# TC37XPD register map
Vendor: Infineon; Series: ATVMC; File version: 100
CPU: other r0p0, little endian, MPU, FPU, vendor SysTick, 4 interrupt priority bits
Registers are 32-bit, read-write, reset 0x0 unless marked. A register's access mark holds for its fields unless they carry their own. Offsets are from the block's base; [hi:lo] are bit positions; {n}, {i} and the like mark numbered series.

## PMS (part 2 of 3)
Base 0xF0248000
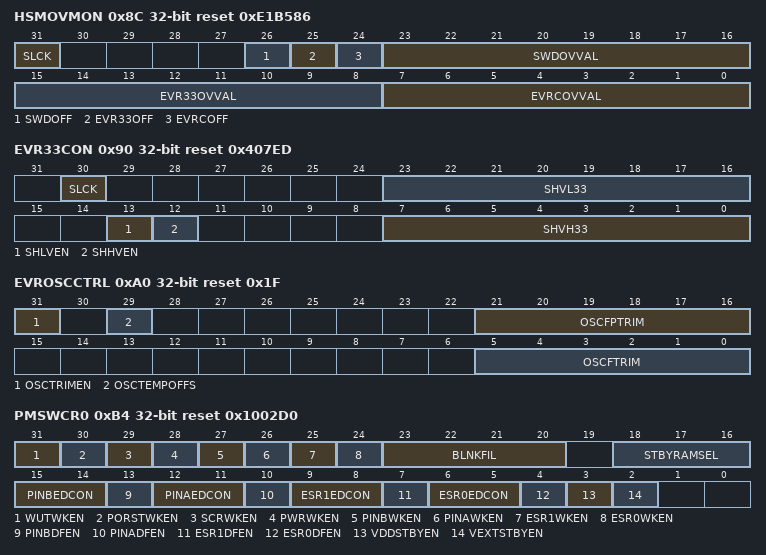
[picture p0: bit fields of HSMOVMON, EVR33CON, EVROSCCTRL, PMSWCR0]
0x8C HSMOVMON reset 0xE1B586 — EVR Primary HSM Over voltage Monitor Register resetvalue={LVD Reset:0x0E1B586,Cold PORST:0x0E1B586,After SSW execution:0x0E1B586}
  [31] SLCK — HSM Security Lock SLCK. If this bit is set all other bits in this register can no longer be written. Write requests to other bits when SLCK is set will trigger an SLCK access error alarm.This bit can not by cleared by software. SLCK bit can only be set by an access from the HSM master TAG 160 160 000011 B . A set operation performed by any other master or software is ignored and the bit is kept as cleared.
  [26] SWDOFF — VEXT Primary Monitor OV Alarm Disable SWDOFF
  [25] EVR33OFF — VDDP3 Primary Monitor OV Alarm Disable EVR33OFF
  [24] EVRCOFF — VDD Primary Monitor OV Alarm Disable EVRCOFF
  [23:16] SWDOVVAL — VEXT Supply Primary Monitor Alarm Over voltage threshold SWDOVVAL. This field defines the over voltage threshold level of the external VEXT supply monitor. SWDOVVAL VDDx 1050 mV LSB LSB 20 mV
  [15:8] EVR33OVVAL — VDDP3 Supply Primary Monitor Alarm Over voltage threshold EVR33OVVAL. This field defines the over voltage monitoring threshold level of the EVR33 regulator output or VDDP3 supply. EVR33OVVAL VDDx 937.5 mV LSB LSB 15 mV
  [7:0] EVRCOVVAL — VDD Supply Primary Monitor Alarm Over voltage threshold EVRCOVVAL. This field defines the over voltage monitoring threshold level of the EVRC regulator output or VDD supply. EVRCOVVAL VDDx 712.5 mV LSB LSB 5 mV
0x90 EVR33CON reset 0x407ED — EVR33 Control Register resetvalue={LVD Reset:0x407ED,Cold PORST:0x407ED,After SSW execution:0x407ED}
  [30] SLCK — HSM Security Lock SLCK. If this bit is set all other bits in this register can no longer be written. Write requests to other bits when SLCK is set will trigger an SLCK access error alarm.This bit can not by cleared by software. SLCK bit can only be set by an access from the HSM master TAG 160 160 000011 B . A set operation performed by any other master or software is ignored and the bit is kept as cleared.
  [23:16] SHVL33 — Short to Ground Voltage Threshold x i SHVL33. This field defines the lower threshold level VDDP3 supply. EVR33 short to ground alarm has the nominal values of SHVL33 1V and t33SHLV 3ms. Do not change the reset value SHVL33 VDDx 937.5 mV LSB LSB 15 mV
  [13] SHLVEN — Short to Low Detection Enable SHLVEN
  [12] SHHVEN — Short to High Detection Enable SHHVEN
  [7:0] SHVH33 — Short to Supply Voltage Threshold x i SHVH33. This field defines the upper threshold level VDDP3 supply. EVR33 short to supply alarm has the nominal values of SHVH33 4.5V and t33SHHV 3ms. Do not change the reset value SHVH33 VDDx 937.5 mV LSB LSB 15 mV
0xA0 EVROSCCTRL reset 0x1F (reset mask 0xDFFFFFFF) — EVR Oscillator Control Register resetvalue={LVD Reset:0x1F,After SSW execution:0x2000001F}
  [31] OSCTRIMEN — Dynamic Oscillator Trim Enable OSCTRIMEN. Based on temperature Oscillator can be trimmed.
  [29] OSCTEMPOFFS — Oscillator Temperature Offset Coefficient OSCTEMPOFFS. This bitfield enables the centering function of the HPOSC temperature coefficient to compensate for technology variations.
  [21:16] OSCFPTRIM — OSC Fine Trim Signed Value OSCFPTRIM. This bit field allows device individual trimming of the oscillator trim value during application. After updating the trim value a waiting time of 1 160 us is required for the change to take effect. OSCTRx is implicitly added to OSCFPTRIM and saturated to range of 32 to 31
  [5:0] OSCFTRIM — Back up Clock Fine Trim Value OSCFTRIM. This thermometer coded bit field contains information about the 100MHz OSC fine trimming. fBACK ftrim OSCFTRIM OSCFPTRIM OSCTRx if OSCTRIMEN 1 LSBFT MHz LSBFT 110kHz Back up Clock accuracy is documented in datasheet. It is recommended to wait 1 160 us after every fine trim step so that the clock source settles at the new frequency. fBACK ftrim value is saturated to range of 64.
0xB4 PMSWCR0 reset 0x1002D0 — Standby and Wake up Control Register 0 resetvalue={LVD Reset:0x1002D0}
  [31] WUTWKEN — WUT Wake up enable from Standby WUTWKEN. This bit configures wake up via WUT from STANDBY mode and current configuration is reflected in PMSWSTAT2.WUTWKEN register bit.
  [30] PORSTWKEN — PORST pin Wake up enable from Standby PORSTWKEN. This bit configures wake up via PORST pin from STANDBY mode and current configuration is reflected in PMSWSTAT2.PORSTWKEN register bit.
  [29] SCRWKEN — Standby Controller Wake up enable from Standby SCRWKEN. This bit configures wake up via SCR from STANDBY mode and current configuration is reflected in PMSWSTAT2.SCRWKEN register bit.
  [28] PWRWKEN — Standby Wake up Enable on VEXT Supply ramp up PWRWKEN. This bit field enables wake up on VEXT supply ramp up after blanking filter time has expired. This is supported only in case Standby domain is supplied separately via VEVRSB supply pin and VEXT rail is switched off during Standby. Current configuration is reflected in PMSWSTAT2.PWRWKEN register bit.
  [27] PINBWKEN — Pin B Wake up enable from Standby PINBWKEN. This bit configures wake up via PINB pin from STANDBY mode and current configuration is reflected in PMSWSTAT2.PINBWKEN register bit.
  [26] PINAWKEN — Pin A Wake up enable from Standby PINAWKEN. This bit configures wake up via PINA pin from STANDBY mode and current configuration is reflected in PMSWSTAT2.PINAWKEN register bit.
  [25] ESR1WKEN — ESR1 Wake up enable from Standby ESR1WKEN. This bit configures wake up via ESR1 pin from STANDBY mode and current configuration is reflected in PMSWSTAT2.ESR1WKEN register bit.
  [24] ESR0WKEN — ESR0 Wake up enable from Standby ESR0WKEN. This bit configures wake up via ESR0 pin from STANDBY mode and current configuration is reflected in PMSWSTAT2.ESR0WKEN register bit.
  [23:20] BLNKFIL — Blanking Filter delay for Wake up BLNKFIL. This bitfield enables a nominal blanking filter delay time immediately after Standby entry only after which a valid wake up event is recognized and reacted upon. The actual delay may vary 160 30 to this nominal value. Current configuration is reflected in PMSWSTAT2.BLNKFIL bitfield. All other bit combinations are reserved. Incase WUT is used as a wake up source the blanking filter should be configured for a period greater than 3x 70kHz clock cycles.
  [18:16] STBYRAMSEL — Standby RAM supply in Standby Mode STBYRAMSEL. This bit field configures the Standby RAM blocks to be kept supplied during Standby Mode from VDDPD supply rail. The current configuration is reflected in PMSWSTAT2.STBYRAM bitfield. All other bit combinations are reserved.
  [15:14] PINBEDCON — PINB Edge Detection Control PINBEDCON. This bit field defines the edge of a Pin B wake up trigger
  [13] PINBDFEN — PINB Digital Filter Enable PINBDFEN. This bit activates digital spike filter. If the digital filter majority filter of 3 consecutive values is enabled during normal RUN mode then pulses less than 40ns are suppressed and pulses longer than 100ns will always result in a trigger. If the back up clock is disabled in Standby mode and filter is running on 70 KHz Standby clock then pulses less than 5 us are suppressed and pulses longer than 50 us will always result in a trigger.
  [12:11] PINAEDCON — PINA Edge Detection Control PINAEDCON. This bit field defines the edge of a Pin A wake up trigger
  [10] PINADFEN — PINA Digital Filter Enable PINADFEN. This bit activates digital spike filter. If the digital filter majority filter of 3 consecutive values is enabled during normal RUN mode then pulses less than 40ns are suppressed and pulses longer than 100ns will always result in a trigger. If the back up clock is disabled in Standby mode and filter is running on 70 KHz Standby clock then pulses less than 5 us are suppressed and pulses longer than 50 us will always result in a trigger.
  [9:8] ESR1EDCON — ESR1 Edge Detection Control ESR1EDCON. This bit field defines the edge of a ESR1 wake up trigger
  [7] ESR1DFEN — ESR1 Digital Filter Enable ESR1DFEN. This bit activates digital spike filter. If the digital filter majority filter of 3 consecutive values is enabled during normal RUN mode then pulses less than 30ns are suppressed and pulses longer than 100ns will always result in a trigger. If the back up clock is disabled in Standby mode and filter is running on 70 KHz Standby clock then pulses less than 5 us are suppressed and pulses longer than 50 us will always result in a trigger.
  [6:5] ESR0EDCON — ESR0 Edge Detection Control ESR0EDCON. This bit field defines the edge of a ESR0 wake up trigger
  [4] ESR0DFEN — ESR0 Digital Filter Enable ESR0DFEN. This bit activates digital spike filter. If the digital filter majority filter of 3 consecutive values is enabled during normal RUN mode then pulses less than 30ns are suppressed and pulses longer than 100ns will always result in a trigger. If the back up clock is disabled in Standby mode and filter is running on 70 160 KHz Standby clock then pulses less than 5 us are suppressed and pulses longer than 50 us will always result in a trigger.
  [3] VDDSTBYEN — Standby Entry on VDD Supply ramp down VDDSTBYEN. This bit field enables Standby Entry on VDD supply ramp down. This is supported only in case Standby domain is supplied separately via VEVRSB supply pin and VDD rail is switched off during Standby. The voltage threshold for entry is configured in EVRUVMON register. Current configuration is reflected in PMSWSTAT2.VDDSTBYEN register bit.
  [2] VEXTSTBYEN — Standby Entry on VEXT Supply ramp down VEXTSTBYEN. This bit field enables Standby Entry on VEXT supply ramp down. This is supported only in case Standby domain is supplied separately via VEVRSB supply pin and VEXT rail is switched off during Standby. The voltage threshold for entry is configured in EVRUVMON register. Current configuration is reflected in PMSWSTAT2.VEXTSTBYEN register bit.
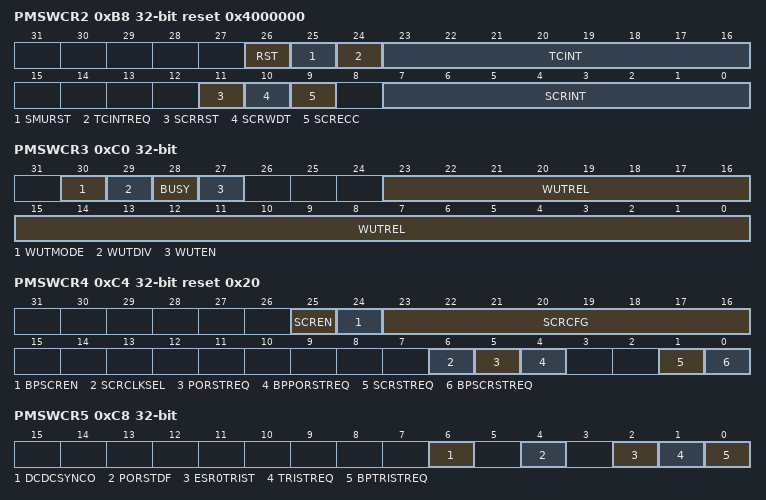
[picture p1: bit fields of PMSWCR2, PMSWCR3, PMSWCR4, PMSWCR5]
0xB8 PMSWCR2 access per field reset 0x4000000 — Standby and Wake up Control Register 2 resetvalue={LVD Reset:0x4000000}
  [26] RST ro — Application or System Reset indication flag RST. SCR is explicitly informed in case of an application or system reset. The flag is cleared after SCR has latched the signal and SCR NMI is issued.
  [25] SMURST ro — SMU Reset indication flag SMURST. SCR is explicitly informed in case reset issued by SMU. The flag is cleared after SCR has latched the signal and SCR NMI is issued.
  [24] TCINTREQ rw — SW Interrupt request from PMS to Standby Controller. TCINTREQ. Setting this bit triggers an interrupt to the 8 bit Standby controller. The TCINTREQ bit is cleared after SCR has latched the TCINT value and SCR NMI is issued.
  [23:16] TCINT rw — Data exchange from PMS main domain to Standby Controller. TCINT. This bit field allows fast data exchange from PMS to SCR. The data may be read by SCR consequent to an interrupt request TCINTREQ from PMS CPUx to SCR to decode the interrupt.
  [11] SCRRST rw — SCR Software reset flag SCRRST. The flag is set by SCR and cleared by explicit write to the register bit. The flag is not cleared by SCR. While the SCR is being reset triggered by SCR software this flag is set and clearing the flag is not possible for that duration.
  [10] SCRWDT rw — SCR Watchdog Timer error reset flag SCRWDT. The flag is set by SCR and cleared by explicit write to the register bit. The flag is not cleared by SCR.While the SCR is being reset triggered by SCR watchdog this flag is set and clearing the flag is not possible for that duration.
  [9] SCRECC rw — SCR RAM ECC error reset flag SCRECC. The flag is set by SCR and cleared by explicit write to the register bit. The flag is not cleared by SCR.While the SCR is being reset triggered by SCR RAM ECC error this flag is set and clearing the flag is not possible for that duration.
  [7:0] SCRINT ro — Data exchange from Standby Controller to PMS main domain. SCRINT. This bit field allows fast data exchange from SCR to PMS CPUx. The data maybe read by CPUx consequent to an interrupt from the SCR to decode the interrupt. Incase SCR is enabled at the end of the SCR Firmware routine a value of 80H is set in SCRINT register to indicate that SCR has finished executing the startup code.
0xC0 PMSWCR3 access per field — Standby and Wake up Control Register 3 resetvalue={LVD Reset:0x0}
  [30] WUTMODE rw — WUT mode selection WUTMODE. This bit configures the Wake up Timer mode. The status bit PMSWSTAT.WUTMODE is respectively updated. A write to this register bitfield may trigger immediate update irrespective of the status of BUSY bit.
  [29] WUTDIV rw — WUT clock divider WUTDIV. A write to this register bitfield may trigger immediate update irrespective of the status of BUSY bit.
  [28] BUSY ro — Lock Status LCK. This bit indicates that the register is busy owing to ongoing bus access. The register can be updated with a new value when BUSY bit is cleared. The register requires synchronization to the 70kHz clock domain on a register update.
  [27] WUTEN rw — WUT enable WUTEN. This bit enables the Wake up Timer. The status bit PMSWSTAT.WUTEN is set once Wake up Timer is enabled.
  [23:0] WUTREL rw — WUT reload value. WUTREL. The counter starts counting down from WUTREL value. The current value of counter is indicated in WUTCNT. On WUTCNT underflow a reload WUTCNT 160 160 WUTREL takes place in auto reload mode.
0xC4 PMSWCR4 access per field reset 0x20 (reset mask 0xFDFFFFFF) — Standby and Wake up Control Register 4 resetvalue={LVD Reset:0x20,After SSW execution:0x2000020}
  [25] SCREN rw — Standby Controller Enable request SCREN. SCR MBIST maybe activated independent of this bit.
  [24] BPSCREN wo — Standby Controller Reset request enable BPSCREN
  [23:16] SCRCFG rw — Hardware configuration of the 8 bit SCR controller. SCRCFG. Any change in SCRCFG is followed by a SCRSTREQ reset request of the 8 bit controller to start off in the chosen mode. All other bit combinations are reserved. Writing to PMSWCR4.SCRCFG with values USERMODE1 0 will have an immediate effect on the enabling of debug pins.
  [6] SCRCLKSEL rw — Default Clock selection on Standby Mode Entry SCRCLKSEL
  [5] PORSTREQ rw — SCR Reset behavior on warm PORST in Normal RUN SLEEP mode PORSTREQ
  [4] BPPORSTREQ wo — Bit Protection for PORSTREQ PORSTEN
  [1] SCRSTREQ rw — Standby Controller Reset request SCRSTREQ
  [0] BPSCRSTREQ wo — Standby Controller Reset request enable SCRSTEN
0xC8 PMSWCR5 access per field — Standby and Wake up Control Register 5 resetvalue={LVD Reset:0x0}
  [6] DCDCSYNCO rw — DC DC Synchronisation Output. This bitfield enables the synchronisation output to synchronize the external SMPS regulator with respect to the internal EVRC regulator. This enable bit controls the ENPS signal to the port pin so that the synchronisation signal is also available during active warm PORST phase. If enabled this signal need to be also routed to HW DIR amp HWEN of the port pin.
  [4] PORSTDF rw — PORST Digital Filter enable PORSTDF. This bit field enables additional PORST digital filter 160 tPORSTDF parameter 160 to provide enhanced immunity against spurious spikes. The filter is implemented over 20 cycles x 40 ns clock which results in a total delay between 800ns 2 trimmed fback clock and is active only in operational mode. In Standby mode the filter is implemented over 2 x 70kHz clock such that pulses less than 8 us are suppressed and pulses longer than 70 us will result in a wake up trigger.
  [2] ESR0TRIST rw — ESR0 Tristate enable ESR0TRIST. This bit configures ESR0 pin behavior either as reset output or tristate during Standby mode if VEXT is supplied.
  [1] TRISTREQ rw — Tristate enable TRISTREQ. This bit decides whether pads behave as inputs with weak pull up or tristate on reset assertion de assertion or Standby Wake up transition. After supply ramp up or LVD reset TRISTREQ 160 160 160 HWCFG6.
  [0] BPTRISTREQ wo — Bit protection for Tristate request bit TRISTREQ BPTRISTREQ. Setting this bit enables that bit TRISTREQ can be changed by a write operation.
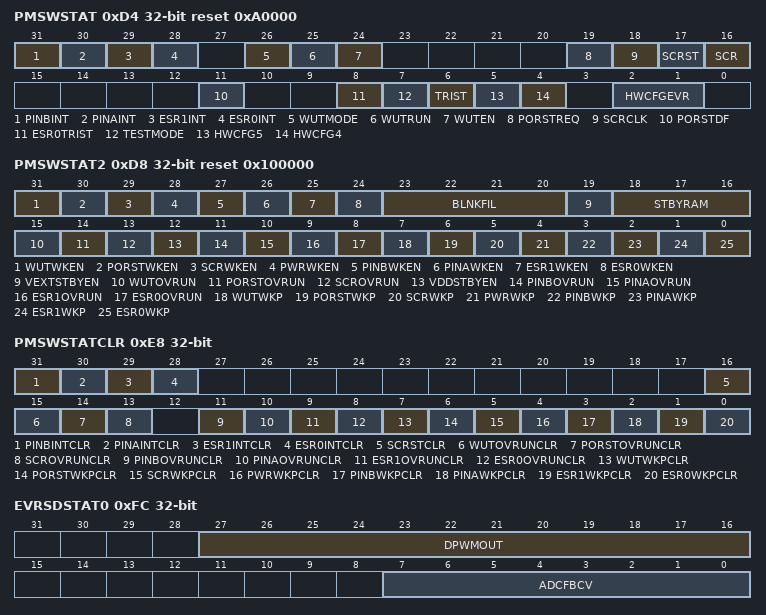
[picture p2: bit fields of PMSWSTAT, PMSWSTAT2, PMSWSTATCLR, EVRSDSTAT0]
0xD4 PMSWSTAT ro reset 0xA0000 — Standby and Wake up Status Register resetvalue={LVD Reset:0x0A0000}
  [31] PINBINT — Pin B Interrupt flag PINBINT. In case interrupt was triggered by PINB pin event during RUN mode this flag is set. The bit shall be cleared explicitly via PMSWSTATCLR.PINBINTCLR bit after interrupt is serviced.
  [30] PINAINT — Pin A Interrupt flag PINAINT. In case interrupt was triggered by PINA pin event during RUN mode this flag is set. The bit shall be cleared explicitly via PMSWSTATCLR.PINAINTCLR bit after interrupt is serviced.
  [29] ESR1INT — ESR1 Interrupt flag ESR1INT. In case interrupt was triggered by ESR1 pin event during RUN mode this flag is set. The bit shall be cleared explicitly via PMSWSTATCLR.ESR1INTCLR bit after interrupt is serviced.
  [28] ESR0INT — ESR0 Interrupt flag ESR0INT. In case interrupt was triggered by ESR0 pin event during RUN mode this flag is set. The bit shall be cleared explicitly via PMSWSTATCLR.ESR0INTCLR bit after interrupt is serviced.
  [26] WUTMODE — WUT Mode status WUTMODE. This bit indicates the current WUT mode. This bit is updated when PMSWCR3.WUTMODE bit is updated.
  [25] WUTRUN — WUT Run status WUTRUN. This bit indicates whether WUT is currently running. Due to synchronization to 70 KHz 160 fSB 160 WUT clock setting of flag after enable may take up to 55 160 us.
  [24] WUTEN — WUT Enable status WUTEN. This bit indicates whether WUT is enabled. This bit is updated when PMSWCR3.WUTEN bit is updated.
  [19] PORSTREQ — Standby Controller Reset on warm PORST PORSTREQ. This bit is updated when PMSWCR4.PORSTREQ bit is set.
  [18] SCRCLK — Current Clock configuration for SCR before Standby Mode Entry SCRCLK. This bit is updated when PMSWCR4.SCRCLKSEL bit is set.
  [17] SCRST — Standby Controller Reset Indication flag SCRST. This bit is set after a power on reset as SCR is in reset state. This bit is consequently set when a reset is issued via PMSWCR4.SCRSTREQ bit. This status flag is set on every SCR reset caused by any SCR reset source.
  [16] SCR — Standby Controller status SCR. This bit indicates whether SCR is enabled. This bit is updated when PMSWCR4.SCREN bit is set.
  [11] PORSTDF — PORST Digital Filter status PORSTDF. This bit field indicates whether additional PORST digital filter is activated. This bit is updated when PMSWCR5.PORSTDF is set.
  [8] ESR0TRIST — ESR0 pin status during Standby ESR0TRIST. This bit indicates if ESR0 pin is configured as reset output or tristate during Standby mode amp transitions if VEXT is supplied.This bit is updated when PMSWCR5. ESR0TRIST is set.
  [7] TESTMODE — TESTMODE Pin status TESTMODE. This bit field indicates the latched level of TESTMODE pin during a cold startup. The HWCFG pin is latched continuously during a period of 60us as measure to improve robustness owing to noise injection.
  [6] TRIST — Pad Tristate Pull up status TRIST. This bit indicates whether pads are configured as inputs with weak pull up or as tristate during after reset or after wake up. At start up the value latched from HWCFG 6 pin decides the default state and is reflected in TRIST status bit. This bit may be later updated when PMSWCR5.TRISTREQ is set to override initial latched status from HWCFG 6 .
  [5] HWCFG5 — Hardware Configuration Pin 5 status HWCFG5. This bit field indicates the latched level of HWCFG 5 during a cold startup. The HWCFG pin is latched continuously during a period of 60us as measure to improve robustness owing to noise injection.
  [4] HWCFG4 — Hardware Configuration Pin 4 status HWCFG4. This bit field indicates the latched level of HWCFG 4 during a cold startup. The HWCFG pin is latched continuously during a period of 60us as measure to improve robustness owing to noise injection.
  [2:1] HWCFGEVR — EVR Hardware Configuration status HWCFGEVR. This bit field indicates the supply configuration latched by the EVR from HWCFG 2 1 during a cold startup based on which EVRx regulators are consequently started. The latched configuration is used during STANDBY RUN transition to reselect EVR mode. The HWCFG pins are latched continuously during a period of 60us as measure to improve robustness owing to noise injection.
0xD8 PMSWSTAT2 ro reset 0x100000 — Standby and Wake up Status Register 2 resetvalue={LVD Reset:0x100000}
  [31] WUTWKEN — WUT Wake up enable status WUTWKEN. This bit indicates that WUT is enabled to trigger wake up from Standby. This bit is updated when PMSWCR0.WUTWKEN bit is updated.
  [30] PORSTWKEN — PORST pin Wake up enable status from Standby PORSTWKEN. This bit indicates that wake up via PORST pin is enabled during STANDBY mode. This bit is updated when PMSWCR0. PORSTWKEN bit is updated.
  [29] SCRWKEN — Standby Controller Wake up Enable status SCRWKEN. This bit indicates that SCR is enabled to trigger wake up from Standby. This bit is updated when PMSWCR0.SCRWKEN bit is updated.
  [28] PWRWKEN — Standby Wake up Enable status on VEXT Supply ramp up PWRWKEN. This bit indicates that VEXT detector is enabled to trigger wake up from Standby during VEXT supply ramp up after blanking filter time has expired. This is supported only when Standby domain is supplied separately by VEVRSB Standby supply pin.This bit is updated when PMSWCR0.PWRWKEN bit is updated.
  [27] PINBWKEN — Pin B Wake up enable status PINBWKEN. This bit indicates that PINB is enabled to trigger wake up from Standby. This bit is updated when PMSWCR0.PINBWKEN bit is updated.
  [26] PINAWKEN — Pin A Wake up enable status PINAWKEN. This bit indicates that PINA is enabled to trigger wake up from Standby. This bit is updated when PMSWCR0.PINAWKEN bit is updated.
  [25] ESR1WKEN — ESR1 Wake up enable status ESR1WKEN. This bit indicates that ESR1 is enabled to trigger wake up from Standby. This bit is updated when PMSWCR0.ESR1WKEN bit is updated.
  [24] ESR0WKEN — ESR0 Wake up enable status ESR0WKEN. This bit indicates that ESR0 is enabled to trigger wake up from Standby. This bit is updated when PMSWCR0.ESR0WKEN bit is updated.
  [23:20] BLNKFIL — Blanking Filter Delay for VEXT Supply Wake up BLNKFIL. This bit field indicates the Blanking filter configuration. This bit field is updated with the value configured in PMSWCR0.BLNKFIL bitfield. All other bit combinations are reserved.
  [19] VEXTSTBYEN — Standby Entry Enable status on VEXT Supply ramp down VEXTSTBYWKEN. This bit indicates that Standby Entry may be triggered on a VEXT Supply undervoltage event SWDUV . This is supported only when Standby domain is supplied separately by VEVRSB Standby supply pin.This bit is updated when PMSWCR0.VEXTSTBYWKEN bit is updated.
  [18:16] STBYRAM — Standby RAM Supply status STBYRAM. This bit field indicates whether Standby RAM was supplied during Standby Mode and to infer status after a wake up event. This bit is updated when PMSWCR0.STBYRAMSEL is set. All other bit combinations are reserved. In case of VDDPD Standby supply fail or VEVRSB supply fail leading to LVD reset indicated also in RSTSTAT.STBYR the STBYRAM status bit is reset to 000b to indicate that Standby RAM contents may be corrupted.
  [15] WUTOVRUN — WUT Overrun status flag WUTOVRUN. This flag indicates that a consecutive WUT wake up event occurred while WUTWKP flag was already set during STANDBY. The bit shall be cleared explicitly after wakeup via PMSWSTATCLR.WUTOVRUNCLR bit before next STANDBY entry. WUTREL need to be greater than 10 during Standby mode to be able to latch consecutive WUT underflow events and update the WUTOVRRUN register bitfield.
  [14] PORSTOVRUN — PORST Overrun status flag PORSTOVRUN. This flag indicates that a consecutive PORST wake up event occurred while PORSTWKP flag was already set during STANDBY. The bit shall be cleared explicitly after wakeup via PMSWSTATCLR.PORSTOVRUNCLR bit before next STANDBY entry.
  [13] SCROVRUN — SCR Overrun status flag SCROVRUN. This flag indicates that a consecutive SCR wake up event occurred while SCRWKP flag was already set during STANDBY. The bit shall be cleared explicitly after wakeup via PMSWSTATCLR.SCROVRUNCLR bit before next STANDBY entry.
  [12] VDDSTBYEN — Standby Entry Enable status on VDD Supply ramp down VDDSTBYWKEN. This bit indicates that Standby Entry may be triggered on a VDD Supply undervoltage event VDDUV . This is supported only when Standby domain is supplied separately by VEVRSB Standby supply pin.This bit is updated when PMSWCR0.VDDSTBYWKEN bit is updated.
  [11] PINBOVRUN — Pin B Overrun status flag PINBOVRUN. This flag indicates that a consecutive PINB wake up event occurred while PINBWKP flag was already set during STANDBY. The bit shall be cleared explicitly after wakeup via PMSWSTATCLR.PINBOVRUNCLR bit before next STANDBY entry.
  [10] PINAOVRUN — Pin A Overrun status flag PINAOVRUN. This flag indicates that a consecutive PINA wake up event occurred while PINAWKP flag was already set during STANDBY. The bit shall be cleared explicitly after wakeup via PMSWSTATCLR.PINAOVRUNCLR bit before next STANDBY entry.
  [9] ESR1OVRUN — ESR1 Overrun status flag ESR1OVRUN. This flag indicates that a consecutive ESR1 wake up event occurred while ESR1WKP flag was already set during STANDBY. The bit shall be cleared explicitly after wakeup via PMSWSTATCLR.ESR1OVRUNCLR bit before next STANDBY entry.
  [8] ESR0OVRUN — ESR0 Overrun status flag ESR0OVRUN. This flag indicates that a consecutive ESR0 wake up event occurred while ESR0WKP flag was already set during STANDBY. The bit shall be cleared explicitly after wakeup via PMSWSTATCLR.ESR0OVRUNCLR bit before next STANDBY entry.
  [7] WUTWKP — WUT Wake up flag WUTWKP. In case wake up was triggered by Wake up timer during STANDBY this flag is set. The bit shall be cleared explicitly after wakeup via PMSWSTATCLR.WUTWKPCLR bit before next STANDBY entry.
  [6] PORSTWKP — PORST Wake up flag PORSTWKP. In case wake up was triggered by PORST pin during STANDBY this flag is set. The bit shall be cleared explicitly after wakeup via PMSWSTATCLR.PORSTWKPCLR bit before next STANDBY entry.
  [5] SCRWKP — SCR Wake up flag SCRWKP. In case wake up is triggered by SCR to the main controller during STANDBY this flag is set. The bit shall be cleared explicitly after wakeup via PMSWSTATCLR.SCRWKPCLR bit before next STANDBY entry.
  [4] PWRWKP — Wake up event on VEXT Supply ramp up PWRWKP. In case wake up was triggered by VEXT ramp up pin during STANDBY this flag is set. The bit shall be cleared explicitly after wakeup via PMSWSTATCLR.PWRWKPCLR bit before next STANDBY entry.
  [3] PINBWKP — Pin B Wake up flag PINBWKP. In case wake up was triggered by PINB pin during STANDBY this flag is set. The bit shall be cleared explicitly after wakeup via PMSWSTATCLR.PINBWKPCLR bit before next STANDBY entry.
  [2] PINAWKP — Pin Wake up flag PINAWKP. In case wake up was triggered by PINA pin during STANDBY this flag is set. The bit shall be cleared explicitly after wakeup via PMSWSTATCLR.PINAWKPCLR bit before next STANDBY entry.
  [1] ESR1WKP — ESR1 Wake up flag ESR1WKP. In case wake up was triggered by ESR1 pin during STANDBY this flag is set. The bit shall be cleared explicitly after wakeup via PMSWSTATCLR.ESR1WKPCLR bit before next STANDBY entry.
  [0] ESR0WKP — ESR0 Wake up flag ESR0WKP. In case wake up was triggered by ESR0 pin during STANDBY this flag is set. The bit shall be cleared explicitly after wakeup via PMSWSTATCLR.ESR0WKPCLR bit before next STANDBY entry.
0xDC PMSWUTCNT ro — Standby WUT Counter Register resetvalue={LVD Reset:0x0}
  [23:0] WUTCNT — WUT counter value. WUTCNT. The current WUT counter value is indicated in this register bitfield. The WUTCNT value may have a deviation of 3 additional clock cycles to the expected counter value owing to synchronization overheads. The WUT clock is based on standby 70 kHz clock with 160 30 variation. The counter depending on the mode can run through a RUN to STANDBY to RUN mode transition without interruption.
0xE8 PMSWSTATCLR wo — Standby and Wake up Status Clear Register resetvalue={LVD Reset:0x0}
  [31] PINBINTCLR — PINB Interrupt indication flag clear PINBINTCLR
  [30] PINAINTCLR — PINA Interrupt indication flag clear PINAINTCLR
  [29] ESR1INTCLR — ESR1 Interrupt indication flag clear ESR1INTCLR
  [28] ESR0INTCLR — ESR0 Interrupt indication flag clear ESR0INTCLR
  [16] SCRSTCLR — Standby controller SCRST indication flag clear SCRSTCLR
  [15] WUTOVRUNCLR — WUT Overrun status indication flag clear WUTOVRUNCLR
  [14] PORSTOVRUNCLR — PORST Overrun status indication flag clear PORSTOVRUNCLR
  [13] SCROVRUNCLR — SCR Overrun status indication flag clear SCROVRUNCLR
  [11] PINBOVRUNCLR — PINB Overrun status indication flag clear PINBOVRUNCLR
  [10] PINAOVRUNCLR — PINA Overrun status indication flag clear PINAOVRUNCLR
  [9] ESR1OVRUNCLR — ESR1 Overrun status indication flag clear ESR1OVRUNCLR
  [8] ESR0OVRUNCLR — ESR0 Overrun status indication flag clear ESR0OVRUNCLR
  [7] WUTWKPCLR — WUT Wake up indication flag clear WUTWKPCLR
  [6] PORSTWKPCLR — PORST Wake up indication flag clear PORSTWKPCLR
  [5] SCRWKPCLR — SCR Wake up indication flag clear SCRWKPCLR
  [4] PWRWKPCLR — PWRWKP Wake up indication flag clear PWRWKPCLR
  [3] PINBWKPCLR — PINB Wake up indication flag clear PINBWKPCLR
  [2] PINAWKPCLR — PINA Wake up indication flag clear PINAWKPCLR
  [1] ESR1WKPCLR — ESR1 Wake up indication flag clear ESR1WKPCLR
  [0] ESR0WKPCLR — ESR0 Wake up indication flag clear ESR0WKPCLR
0xFC EVRSDSTAT0 ro — EVR SD Status Register 0 resetvalue={LVD Reset:0x0,Cold PORST:0x0}
  [27:16] DPWMOUT — DPWM Control Output Status DPWMOUT. This bit field reflects the actual PWM output of the controller provided to the external MOSFET switches.
  [7:0] ADCFBCV — Step Down Converter Core Voltage Feedback ADC Conversion Result ADCFBCV. This bit field indicates the last ADC conversion result of the step down converter feedback ADC measuring VDD core voltage. VIN xa0 xa0 LSB xa0 xa0 ADCFBCV xa0 xa0 EVRTRIM.SDVOUTTRIM 0.7125 xa0 V xa0 xa0 LSB 5 xa0 mV E.g. 1.20 xa0 V 62 98
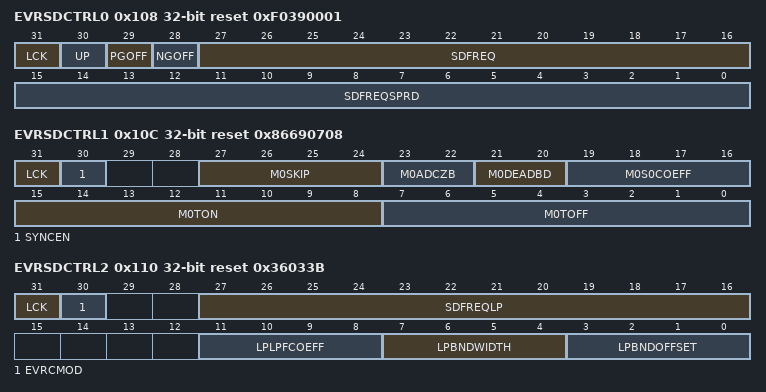
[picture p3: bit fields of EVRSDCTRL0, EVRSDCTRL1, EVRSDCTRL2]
0x108 EVRSDCTRL0 access per field reset 0xF0390001 — EVRC SD Control Register 0 resetvalue={LVD Reset:0x0F0390001,Cold PORST:0x0F0390001,After SSW execution:0x0F0390001}
  [31] LCK ro — Lock Status LCK. This bit indicates if the register can be updated with a new value or if the register is locked and a write action from the bus side has no effect. When UP bit is set to 1 register is locked for shadow register update and LCK bit is set to 1. Once shadow register update is done the lock is released and LCK bit is set to 0.
  [30] UP rw — Update request for SMPS register values UP. This bitfield triggers the update of the current register values from PMS FPI EVRC registers to the local SMPS module registers. It shall be ensured that ALL EVRSDCTRLx and EVRSDCOEFFx registers have correct and coherent values across the various registers before the update request is issued. Incase of singular register update the other register values should match and be consistent. After a cold PORST the UP bit is set as default reset value to ensure that the complete SMPS regulator parameter set is set back to its reset state. Consequently the UP bit is reset and a read delivers 0. The parameter update via UP bit is not allowed in start up and low power mode.
  [29] PGOFF rw — PMOS level during OFF state drvslo pgoff i PGOFF. This bitfield configures the state of Pch. MOSFET driver during start up and shut down phases.
  [28] NGOFF rw — NMOS level during OFF state drvslo ngoff i NGOFF. This bit field configures the state of N ch. MOSFET driver during start up and shut down phases.
  [27:16] SDFREQ rw — Regulator Switching Frequency or Over sampling Factor m0osfl fact i m0osfh fact i SDFREQ. This bit field configures the EVRC regulator switching frequency during closed loop operation.The switching frequency is equal to 100 160 MHz SDFREQ 1 value. SDFREQ represents the corresponding over sampling factor or clock cycles in a period.
  [15:0] SDFREQSPRD rw — Frequency Spread Threshold freqsp coeff i SDFREQSPRD. This bit field defines the additional frequency spread to the nominal EVRC regulator switching frequency during operation
0x10C EVRSDCTRL1 access per field reset 0x86690708 — EVRC SD Control Register 1 resetvalue={LVD Reset:0x086690708,Cold PORST:0x086690708,After SSW execution:0x086690708}
  [31] LCK ro — Lock Status LCK. This bit indicates if the register can be updated with a new value or if the register is locked and a write action from the bus side has no effect. When EVRSDCTRL0.UP bit is set to 1 register is locked for shadow register update and LCK bit is set to 1. Once shadow register update is done the lock is released and LCK bit is set to 0.
  [30] SYNCEN rw — EVRC Synchronization input enable synci0 en i SYNCEN. This bitfield enables the input synchronization logic of EVRC SMPS regulator. When set to 1 the DCDC will start to lock to the external synchronization input signal. This EVRC Synchronization status is indicated in EVRSTAT.SYNCLCK status bits.
  [27:24] M0SKIP rw — Skip Pulse Threshold m0skip thres i M0SKIP. This bitfield specifies the threshold to detect a skip pulse condition during closed loop operation. N channel MOSFET .
  [23:22] M0ADCZB rw — ADC Zero Bin m0fcfg adczb i M0ADCZB. This bitfield specifies the zero error bin during closed loop operation.
  [21:20] M0DEADBD rw — Dead Band m0s0 deadbd i M0DEADBD. This bitfield specifies the dead band to block the ADC ripple during closed loop operation.
  [19:16] M0S0COEFF rw — S0 coefficient m0s0 coeff i M0S0COEFF. This bitfield indicates the S0 coefficient during closed loop operation.
  [15:8] M0TON rw — Minimum On Time m0ton minton i M0TON. This bitfield configures the minimum on time within one period in 100MHz clock cycle periods during closed loop operation.
  [7:0] M0TOFF rw — Minimum Off Time m0toff mintof i M0TOFF. This bitfield configures the minimum off time within one period in 100MHz clock cycle periods during closed loop operation.
0x110 EVRSDCTRL2 access per field reset 0x36033B — EVRC SD Control Register 2 resetvalue={LVD Reset:0x36033B,Cold PORST:0x36033B,After SSW execution:0x36033B}
  [31] LCK ro — Lock Status LCK. This bit indicates if the register can be updated with a new value or if the register is locked and a write action from the bus side has no effect. When EVRSDCTRL0.UP bit is set to 1 register is locked for shadow register update and LCK bit is set to 1. Once shadow register update is done the lock is released and LCK bit is set to 0.
  [30] EVRCMOD rw — LPM or PWM EVRC Mode Activation EVRCMOD. This bit switches operation mode between PWM and LPM mode.
  [27:16] SDFREQLP rw — Regulator Over sampling Factor m1osfl fact i m1osfh fact i SDFREQLP. This bitfield configures the EVRC regulator FB ADC sampling period during low power mode. The switching frequency is not constant.
  [11:8] LPLPFCOEFF rw — Low Pass Filter Coefficient lplpf coeff i LPLPFCOEFF. This bit field configures the low pass filter coefficient for the setting of the turn on threshold of the Sliding function.
  [7:4] LPBNDWIDTH rw — Low Power Mode Hysteresis Band Width lpbnd width i LPBNDWIDTH. This bitfield defines the turn on threshold in LP mode.
  [3:0] LPBNDOFFSET rw — Low Power Mode Hysteresis OFFSET lpbnd offset i LPBNDOFFSET. This bitfield defines the turn on threshold in LP mode
